# A33M11x register map
Vendor: ABOV Semiconductor Co., Ltd.; File version: 1.0
CPU: CM3 r0p1, little endian, MPU, FPU, VTOR, 4 interrupt priority bits
Registers are 32-bit, read-write, reset 0x0 unless marked. A register's access mark holds for its fields unless they carry their own. Offsets are from the block's base; [hi:lo] are bit positions; {n}, {i} and the like mark numbered series.

## PA — General Port A
Base 0x40001000
Same registers: PB 0x40001100, PC 0x40001200, PD 0x40001300, PF 0x40001500, PG 0x40001600
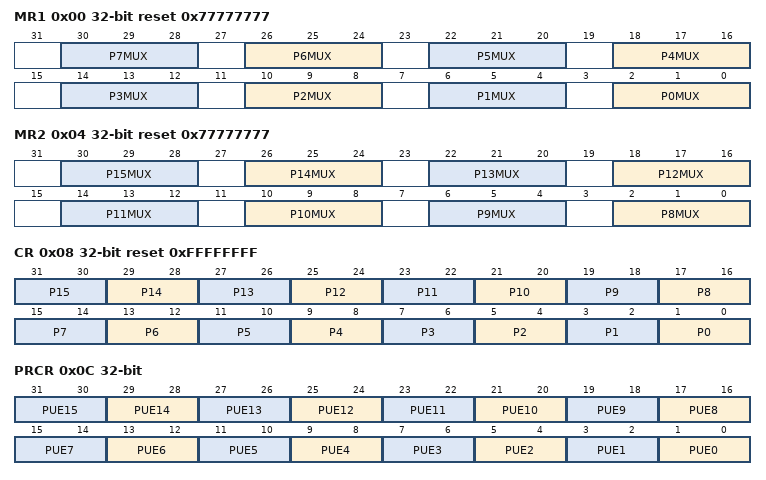
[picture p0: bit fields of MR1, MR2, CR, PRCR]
0x00 MR1 reset 0x77777777 — Port n MUX1 Selection Register
  [4n+2:4n] P{n}MUX (n=0..7) — Pin {n} Mode Selection bits
0x04 MR2 reset 0x77777777 — Port n MUX2 Selection Register
  [4n-30:4n-32] P{n}MUX (n=8..15) — Pin {n} Mode Selection bits
0x08 CR reset 0xFFFFFFFF — Port n Type Selection Register
  [2n+1:2n] P{n} (n=0..15) — Pin {n} Type Selection bit
0x0C PRCR — Port n Pull-up/down Selection Register
  [2n+1:2n] PUE{n} (n=0..15) — Pin {n} Pull-up/down Selection bits
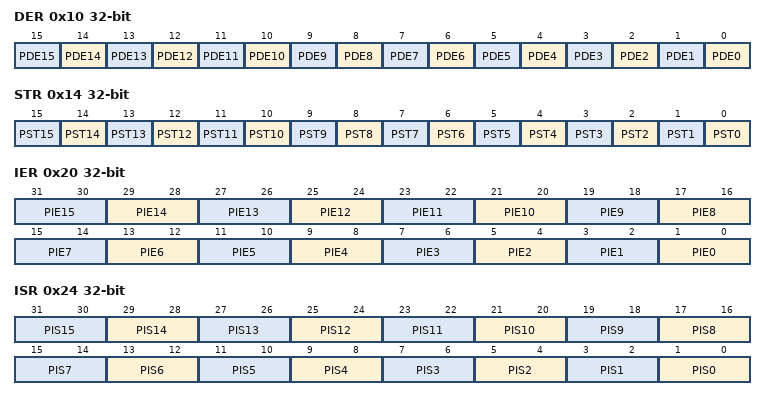
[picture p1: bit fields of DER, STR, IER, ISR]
0x10 DER — Port n Debounce Enable Register
  [n] PDE{n} (n=0..15) — Pin {n} Debounce Enable bits
0x14 STR — Port n Strength Selection Register
  [n] PST{n} (n=0..15) — Pin {n} Strength Selection bit
0x20 IER — Port n Interrupt Enable Register
  [2n+1:2n] PIE{n} (n=0..15) — Pin {n} Interrupt Enable bit
0x24 ISR — Port n Interrupt Status Register
  [2n+1:2n] PIS{n} (n=0..15) — Pin {n} Interrupt Status bit
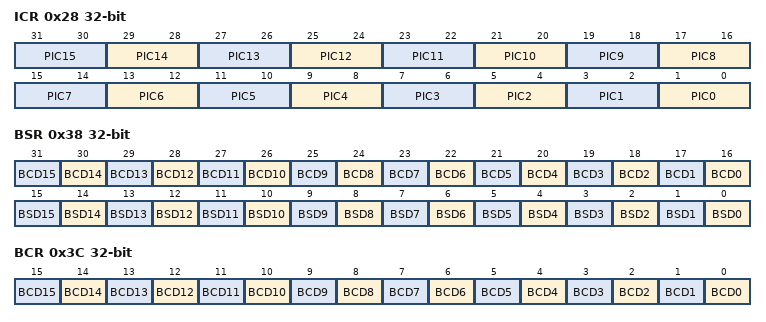
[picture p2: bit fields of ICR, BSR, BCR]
0x28 ICR — Port n Interrupt Control Register
  [2n+1:2n] PIC{n} (n=0..15) — Pin {n} Interrupt Control bit
0x30 ODR — Port n Output Data Register
  [15:0] POD — Pin Output Data bit
0x34 IDR ro — Port n Input Data Register
  [15:0] PID — Port Input Data bits
0x38 BSR wo (reset mask 0xFFFF) — Port n Output Bit Set Register
  [n+16] BCD{n} (n=0..15) — Port {n} Output Clear bits
  [n] BSD{n} (n=0..15) — Port {n} Output Set bits
0x3C BCR wo — Port n Output Bit Clear Register
  [n] BCD{n} (n=0..15) — Port {n} Output Clear bits

## PORTEN — General Port Access Enable
Base 0x40001FF0
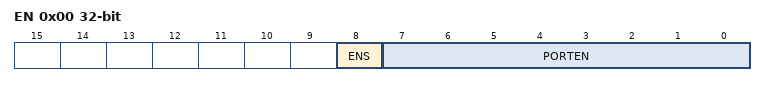
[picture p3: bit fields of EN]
0x00 EN wo (reset mask 0xFF) — Port Access Enable Register
  [8] ENS ro — Enable Status Bit
  [7:0] PORTEN — Port Access Enable bit, write sequence 0x15, 0x51

## DFMC — DATA FLASH MEMORY CONTROLLER
Base 0x41001000
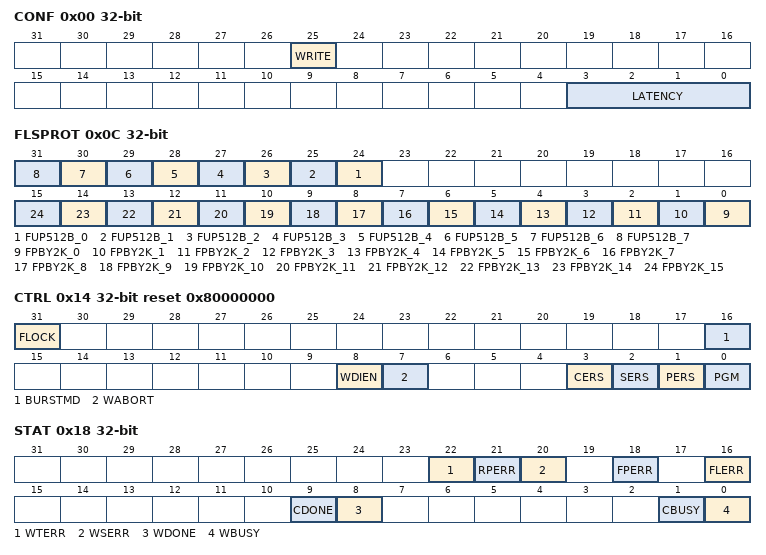
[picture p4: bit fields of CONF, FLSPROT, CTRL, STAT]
0x00 CONF — Flash Memory Control Register
  [25] WRITE — Flash Write Enable Bit
  [3:0] LATENCY — Flash Wait Value Bits
0x04 FLSKEY — Flash Memory Access Key Register
  [31:0] FKEY — Flash Memory Access Key, KEY1(0x01234567) -> KEY2(0x12345678) -> KEY3(0x23456789)
0x0C FLSPROT — Flash Memory Protection Register
  [n+24] FUP512B_{n} (n=0..7) — Flash upper 4KB Unprotection
  [n] FPBY2K_{n} (n=0..15) — Flash 2KB Protection
0x14 CTRL reset 0x80000000 — Flash Access Control Register
  [31] FLOCK — Flash Lock Setting Bit
  [16] BURSTMD — Burst PGM Mode Setting Bit
  [8] WDIEN — Write done interrupt enable bit
  [7] WABORT — Write abort enable bit
  [3] CERS — Chip Erase Mode Bit
  [2] SERS — Sector 2KB Erase Mode
  [1] PERS — Page Erase Mode
  [0] PGM — Program Mode
0x18 STAT — Flash Access Status Register
  [22] WTERR — Write Timeout Error(Auto Cleared)
  [21] RPERR — Read Protect Error(Auto Cleared)
  [20] WSERR — Write Sequence Error (Auto Cleared)
  [18] FPERR — Flash Protect Error (Auto Cleared)
  [16] FLERR — Flash Lock Error (Auto Cleared)
  [9] CDONE — Checksum Done Check (Auto Cleared)
  [8] WDONE — Write Done Check (Auto Cleared)
  [1] CBUSY ro — Checksum Busy Check
    0=Not Busy (Checksum Not Busy); 1=Busy (Checksum Busy)
  [0] WBUSY ro — Write Busy Check
    0=Not Busy (Checksum Not Busy); 1=Busy (Checksum Busy)
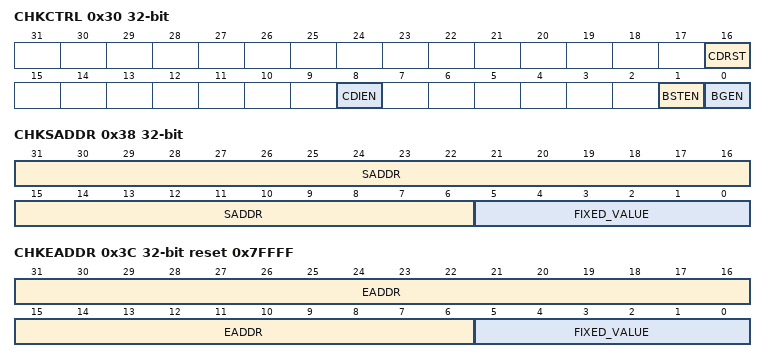
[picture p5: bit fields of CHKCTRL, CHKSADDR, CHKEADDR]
0x30 CHKCTRL — Flash Checksum Control Register
  [16] CDRST — Checksum Data Reset (Auto Cleared)
    0=No Effect; 1=Reset
  [8] CDIEN — Checksum Done Interrupt
    0=Disable; 1=Enable
  [1] BSTEN — Burst Mode
    0=Disable; 1=Enable
  [0] BGEN — Back Ground Mode
    0=Disable; 1=Enable
0x34 CHKDOUT reset 0xFFFF — Flash Checksum Data Output Register
  [15:0] CDOUT ro — Flash Checksum Data Output bit
0x38 CHKSADDR — Flash Checksum Start Address Resgister
  [31:6] SADDR — Flash Checksum Start Address bit
  [5:0] FIXED_VALUE ro — Fixed Vaule
0x3C CHKEADDR reset 0x7FFFF — Flash Checksum End Address Register
  [31:6] EADDR — Flash Checksum End Address bit
  [5:0] FIXED_VALUE ro
0x40 WTIMEOUT — Flash Write Timeout Register
  [7:0] WTIMEOUT — Flash Write Timeout Setting bit

## Notices in the file
Copyright (C) 2012-2014 ARM Limited. All rights reserved.
Purpose: System Viewer Description (SVD) Example (Schema Version 1.1)
This is a description of a none-existent and incomplete device
for demonstration purposes only.
Redistribution and use in source and binary forms, with or without
modification, are permitted provided that the following conditions are met:
- Redistributions of source code must retain the above copyright
notice, this list of conditions and the following disclaimer.
- Redistributions in binary form must reproduce the above copyright
notice, this list of conditions and the following disclaimer in the
documentation and/or other materials provided with the distribution.
- Neither the name of ARM nor the names of its contributors may be used
to endorse or promote products derived from this software without
specific prior written permission.
THIS SOFTWARE IS PROVIDED BY THE COPYRIGHT HOLDERS AND CONTRIBUTORS "AS IS"
AND ANY EXPRESS OR IMPLIED WARRANTIES, INCLUDING, BUT NOT LIMITED TO, THE
IMPLIED WARRANTIES OF MERCHANTABILITY AND FITNESS FOR A PARTICULAR PURPOSE
ARE DISCLAIMED. IN NO EVENT SHALL COPYRIGHT HOLDERS AND CONTRIBUTORS BE
LIABLE FOR ANY DIRECT, INDIRECT, INCIDENTAL, SPECIAL, EXEMPLARY, OR
CONSEQUENTIAL DAMAGES (INCLUDING, BUT NOT LIMITED TO, PROCUREMENT OF
SUBSTITUTE GOODS OR SERVICES; LOSS OF USE, DATA, OR PROFITS; OR BUSINESS
INTERRUPTION) HOWEVER CAUSED AND ON ANY THEORY OF LIABILITY, WHETHER IN
CONTRACT, STRICT LIABILITY, OR TORT (INCLUDING NEGLIGENCE OR OTHERWISE)
ARISING IN ANY WAY OUT OF THE USE OF THIS SOFTWARE, EVEN IF ADVISED OF THE
POSSIBILITY OF SUCH DAMAGE.
